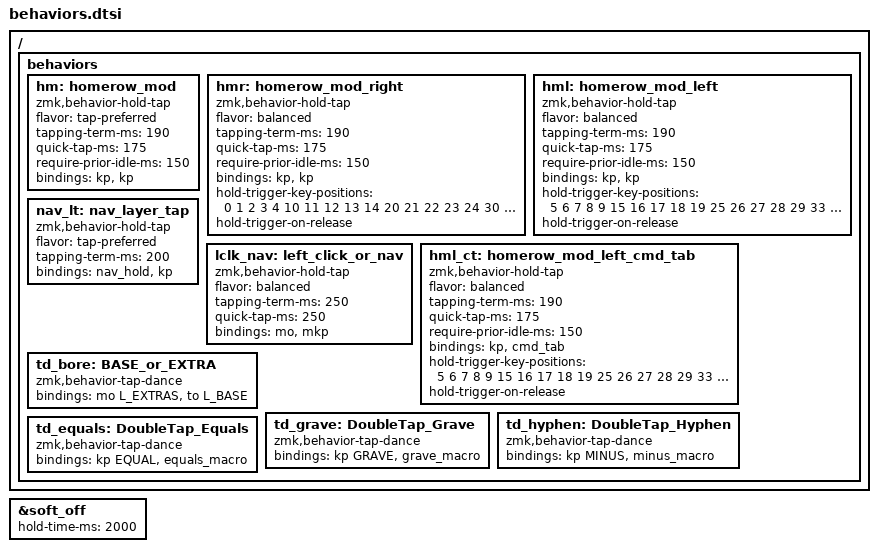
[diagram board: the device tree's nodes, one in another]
/ {
    behaviors {
        // Function-key hold-taps used on the NUM layer (hold F1, tap 1).
        //
        // Deliberately WITHOUT hold-while-undecided: the hold here is a
        // function key, not a modifier, and pressing F1 speculatively on
        // every key-down would fire "help" in a lot of applications.
        //
        // tap-preferred, not balanced, and this is the same concern arriving by
        // a second route. Under "balanced" the hold also fires when another key
        // is pressed AND released inside the tapping term -- so two digits
        // rolled quickly on NUM resolved the first one as a hold and emitted an
        // F-key. require-prior-idle-ms does not cover it: it guards against the
        // key *before* this one, and the first digit after a pause has no such
        // key. Neither do positions -- unlike hml/hmr, this behavior spans both
        // hands, so there is no cross-hand rule to apply.
        //
        // Under tap-preferred only the timer can produce a hold, so no roll at
        // any speed can emit an F-key. The cost is that F-key chords (Cmd+F5)
        // need the 190 ms hold to elapse before the second key, which is how a
        // function key gets pressed anyway. Same reasoning makes ZMK's own &lt
        // tap-preferred by default.
        hm: homerow_mod {
            compatible = "zmk,behavior-hold-tap";
            #binding-cells = <2>;
            flavor = "tap-preferred";
            tapping-term-ms = <190>; // triggers the hold behavior when the tapping-term-ms has expired
            quick-tap-ms = <175>; // If you press a tapped hold-tap again within quick-tap-ms milliseconds of the first press, it will always trigger the tap behavior.
            require-prior-idle-ms = <150>; // like quick-tap-ms however it will apply for any non-modifier key pressed before it
            bindings = <&kp>, <&kp>;  // hold, tap
        };

        // Home-row modifiers: balanced flavor, positional hold-trigger,
        // require-prior-idle, hold-trigger-on-release so mods stack on one
        // hand. That is urob's "timeless" recipe, and it is deliberately all
        // of it -- hold-while-undecided is NOT set here, and was removed
        // rather than never added, so the reason is worth keeping.
        //
        // What it did: press the modifier immediately on key-down, releasing
        // it again if the key resolved into a tap. ZMK documents the use case
        // as "useful for using modifiers with the mouse", which is exactly
        // this board -- two trackballs, and a click is not a key event, so a
        // click alone can never resolve a hold-tap.
        //
        // Why it had to go: it sends a real modifier press AND release to the
        // host on every home-row tap that require-prior-idle-ms does not
        // suppress -- every word-initial a, s, d, f, j, k, l and `;`. Native
        // macOS ignores a stray bare modifier. A remote-desktop client does
        // not: it forwards raw key input into the session, and on Windows a
        // bare Alt tap opens the menu bar, so those letters armed the menu and
        // whatever was typed next went into it. Systematic rather than
        // occasional, because it fires on every single tap.
        //
        // What it costs, which is less than the comment this replaces claimed:
        // modifier-clicking still works. behavior_hold_tap.c maps
        // HT_TIMER_EVENT to STATUS_HOLD_TIMER (line 291), so for the balanced
        // flavor the tapping term expiring resolves a hold on its own, with no
        // second key involved. Cmd-click becomes hold A past 190 ms and then
        // click, instead of hold-and-click instantly. Slower, not gone.
        //
        // Counter-argument, recorded so it is not rediscovered the hard way:
        // zmkfirmware/zmk#759 reports RDP-style clients DROPPING modifiers out
        // of chords, because ZMK emits the mod press and the key press too
        // close together, and hold-while-undecided helps there by sending the
        // mod earlier. That is the opposite failure to the one above. If
        // Cmd+C inside a remote session turns out unreliable, that issue is
        // the explanation -- and the fix is a passthrough layer binding plain
        // &kp across the home row, not turning this property back on, which
        // would just restore the menu-bar problem.
        //
        // Separately, and still true: a position that also takes part in a
        // combo cannot resolve its hold until the combo timeout expires. That
        // applies to F (13) and J (16).
        hmr: homerow_mod_right {
            compatible = "zmk,behavior-hold-tap";
            #binding-cells = <2>;
            flavor = "balanced";
            tapping-term-ms = <190>;
            quick-tap-ms = <175>;
            require-prior-idle-ms = <150>;
            bindings = <&kp>, <&kp>;
            hold-trigger-key-positions = <0 1 2 3 4 10 11 12 13 14 20 21 22 23 24 30 31 32>;
            hold-trigger-on-release;
        };

        hml: homerow_mod_left {
            compatible = "zmk,behavior-hold-tap";
            #binding-cells = <2>;
            flavor = "balanced";
            tapping-term-ms = <190>;
            quick-tap-ms = <175>;
            require-prior-idle-ms = <150>;
            bindings = <&kp>, <&kp>;
            hold-trigger-key-positions = <5 6 7 8 9 15 16 17 18 19 25 26 27 28 29 33 34 35>;
            hold-trigger-on-release;
        };

        // Hold gives EXTRAS, not NAV. NAV moved to the left inner thumb
        // (position 32) because that is how the UHK is held: the Mod key is a
        // left thumb key there, and its layer puts window and tab management
        // under the left fingers with the arrows under the right hand. Holding
        // NAV with the right thumb meant driving the arrows with the same hand
        // that was holding the layer down.
        // td_space, td_bs and td_tab were removed. Each wrapped a layer-tap in
        // a two-entry tap-dance, `<&lt N KEY>, <&kp KEY>`, with an 85 ms term
        // -- and the second entry only repeated what the first one's tap
        // already did, so the tap-dance bought nothing and cost two things.
        //
        // behavior_tap_dance.c emits nothing on the first press: it starts the
        // 85 ms timer and waits. So every Tab, Space and Backspace was delayed
        // 85 ms, and every layer hold cost 85 ms on top of the layer-tap's own
        // 200 ms term before Fn or Extras engaged.
        //
        // Worse, `on_tap_dance_binding_pressed` jumps straight to
        // behaviors[behavior_count - 1] once the counter reaches the binding
        // count, invoking it ONCE. Two fast presses of Backspace therefore
        // deleted one character, not two.
        //
        // The three thumb keys now bind layer-taps directly -- `&lt L_NUM TAB`,
        // `&nav_lt L_NAV SPACE` and `&lt L_NUM BACKSPACE`. Taps are emitted on
        // release with no timer, and repeats are no longer swallowed.

        // NAV's layer-tap. Identical to `&lt` (tap-preferred, 200 ms) except
        // that the hold half is the `nav_hold` macro, which releases Cmd on
        // the way out. That is what closes the app switcher `&cmd_tab` opens
        // on NAV's D -- ZMK has no layer-exit hook, so it hangs off here.
        nav_lt: nav_layer_tap {
            compatible = "zmk,behavior-hold-tap";
            #binding-cells = <2>;
            flavor = "tap-preferred";
            tapping-term-ms = <200>;
            bindings = <&nav_hold>, <&kp>;
        };

        // Left click, or NAV on a long press. Called as `&lclk_nav L_NAV LCLK`.
        //
        // Dragging still works, via quick-tap: click once and press again
        // within quick-tap-ms and the hold-tap is forced to the TAP branch
        // (behavior_hold_tap.c:629 decides HT_QUICK_TAP on key-down), which
        // presses `&mkp LCLK` and holds it until the key is released. So
        // tap-then-hold is a click-and-drag, and a plain long hold is NAV.
        // That is the only way to get both out of one key: a hold-tap decides
        // from timing and key positions alone and cannot see the ball moving.
        //
        // 250 ms rather than the 190 ms used for the home-row mods, on both
        // counts: a slow deliberate click should not turn into a layer, and
        // the double-press for a drag should not need to be hurried.
        lclk_nav: left_click_or_nav {
            compatible = "zmk,behavior-hold-tap";
            #binding-cells = <2>;
            flavor = "balanced";
            tapping-term-ms = <250>;
            quick-tap-ms = <250>;
            bindings = <&mo>, <&mkp>;
        };

        // `hml`, but the tap is the cmd_tab macro instead of a keycode, so
        // NAV's D can be the app switcher and still hold Ctrl -- which is what
        // makes Ctrl+arrow (Mission Control spaces) work from that layer.
        // Called as `&hml_ct LCTRL LGUI`.
        hml_ct: homerow_mod_left_cmd_tab {
            compatible = "zmk,behavior-hold-tap";
            #binding-cells = <2>;
            flavor = "balanced";
            tapping-term-ms = <190>;
            quick-tap-ms = <175>;
            require-prior-idle-ms = <150>;
            bindings = <&kp>, <&cmd_tab>;
            hold-trigger-key-positions = <5 6 7 8 9 15 16 17 18 19 25 26 27 28 29 33 34 35>;
            hold-trigger-on-release;
        };

        td_bore: BASE_or_EXTRA {
            compatible = "zmk,behavior-tap-dance";
            #binding-cells = <0>;
            bindings = <&mo L_EXTRAS>, <&to L_BASE>;
        };

        td_grave: DoubleTap_Grave {
            compatible = "zmk,behavior-tap-dance";
            #binding-cells = <0>;
            bindings = <&kp GRAVE>, <&grave_macro>;
        };

        td_hyphen: DoubleTap_Hyphen {
            compatible = "zmk,behavior-tap-dance";
            #binding-cells = <0>;
            bindings = <&kp MINUS>, <&minus_macro>;
        };

        td_equals: DoubleTap_Equals {
            compatible = "zmk,behavior-tap-dance";
            #binding-cells = <0>;
            bindings = <&kp EQUAL>, <&equals_macro>;
        };

        // Removed as dead code (recoverable from git history):
        //   td_cursor, td_clk_scrl  - both targeted layers 8 and 9, which
        //                             have never existed in this keymap
        //   td_esc, httl, td_layers - defined but never bound
        //   td_home                 - never bound; its grave_macro sibling
        //                             home_macro went with it
    };
};

// Travel power-down, on EXTRAS position 25. Needs CONFIG_ZMK_PM_SOFT_OFF=y,
// which config/arcduo.conf sets for all three units.
//
// 2000 ms rather than the stock instant press. This key sits in the finger
// block next to Mute, and a two-second hold is what makes a slipped finger
// harmless -- the same protection &bootloader cannot have, which is why that
// one is on a dead thumb instead.
//
// The hold time applies to the CENTRAL only. Per ZMK's soft-off docs a
// peripheral "will always enter the soft off state immediately when triggering
// the behavior, regardless of the hold-time-ms setting", so that the central
// cannot power down before it has told the halves to. Waking any unit is a tap
// of its own reset button.
&soft_off {
    hold-time-ms = <2000>;
};
